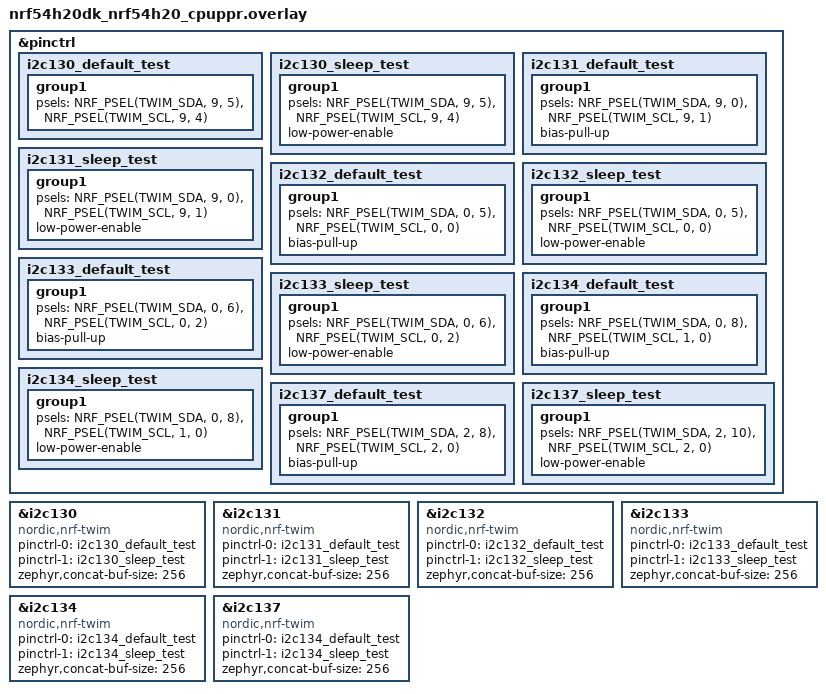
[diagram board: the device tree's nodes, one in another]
/*
 * Copyright (c) 2025 Nordic Semiconductor ASA
 *
 * SPDX-License-Identifier: LicenseRef-Nordic-5-Clause
 */

&pinctrl {
	i2c130_default_test: i2c130_default_test {
		group1 {
			psels = <NRF_PSEL(TWIM_SDA, 9, 5)>,
				<NRF_PSEL(TWIM_SCL, 9, 4)>;
		};
	};

	i2c130_sleep_test: i2c130_sleep_test {
		group1 {
			psels = <NRF_PSEL(TWIM_SDA, 9, 5)>,
				<NRF_PSEL(TWIM_SCL, 9, 4)>;
			low-power-enable;
		};
	};

	i2c131_default_test: i2c131_default_test {
		group1 {
			psels = <NRF_PSEL(TWIM_SDA, 9, 0)>,
				<NRF_PSEL(TWIM_SCL, 9, 1)>;
			bias-pull-up;
		};
	};

	i2c131_sleep_test: i2c131_sleep_test {
		group1 {
			psels = <NRF_PSEL(TWIM_SDA, 9, 0)>,
				<NRF_PSEL(TWIM_SCL, 9, 1)>;
			low-power-enable;
		};
	};

	i2c132_default_test: i2c132_default_test {
		group1 {
			psels = <NRF_PSEL(TWIM_SDA, 0, 5)>,
				<NRF_PSEL(TWIM_SCL, 0, 0)>;
			bias-pull-up;
		};
	};

	i2c132_sleep_test: i2c132_sleep_test {
		group1 {
			psels = <NRF_PSEL(TWIM_SDA, 0, 5)>,
				<NRF_PSEL(TWIM_SCL, 0, 0)>;
			low-power-enable;
		};
	};

	i2c133_default_test: i2c133_default_test {
		group1 {
			psels = <NRF_PSEL(TWIM_SDA, 0, 6)>,
				<NRF_PSEL(TWIM_SCL, 0, 2)>;
			bias-pull-up;
		};
	};

	i2c133_sleep_test: i2c133_sleep_test {
		group1 {
			psels = <NRF_PSEL(TWIM_SDA, 0, 6)>,
				<NRF_PSEL(TWIM_SCL, 0, 2)>;
			low-power-enable;
		};
	};

	i2c134_default_test: i2c134_default_test {
		group1 {
			psels = <NRF_PSEL(TWIM_SDA, 0, 8)>,
				<NRF_PSEL(TWIM_SCL, 1, 0)>;
			bias-pull-up;
		};
	};

	i2c134_sleep_test: i2c134_sleep_test {
		group1 {
			psels = <NRF_PSEL(TWIM_SDA, 0, 8)>,
				<NRF_PSEL(TWIM_SCL, 1, 0)>;
			low-power-enable;
		};
	};

	i2c137_default_test: i2c137_default_test {
		group1 {
			psels = <NRF_PSEL(TWIM_SDA, 2, 8)>,
				<NRF_PSEL(TWIM_SCL, 2, 0)>;
			bias-pull-up;
		};
	};

	i2c137_sleep_test: i2c137_sleep_test {
		group1 {
			psels = <NRF_PSEL(TWIM_SDA, 2, 10)>,
				<NRF_PSEL(TWIM_SCL, 2, 0)>;
			low-power-enable;
		};
	};
};

&i2c130 {
	compatible = "nordic,nrf-twim";
	status = "okay";
	pinctrl-0 = <&i2c130_default_test>;
	pinctrl-1 = <&i2c130_sleep_test>;
	pinctrl-names = "default", "sleep";
	zephyr,concat-buf-size = <256>;
};

&i2c131 {
	compatible = "nordic,nrf-twim";
	status = "okay";
	pinctrl-0 = <&i2c131_default_test>;
	pinctrl-1 = <&i2c131_sleep_test>;
	pinctrl-names = "default", "sleep";
	zephyr,concat-buf-size = <256>;
};

&i2c132 {
	compatible = "nordic,nrf-twim";
	status = "okay";
	pinctrl-0 = <&i2c132_default_test>;
	pinctrl-1 = <&i2c132_sleep_test>;
	pinctrl-names = "default", "sleep";
	zephyr,concat-buf-size = <256>;
};

&i2c133 {
	compatible = "nordic,nrf-twim";
	status = "okay";
	pinctrl-0 = <&i2c133_default_test>;
	pinctrl-1 = <&i2c133_sleep_test>;
	pinctrl-names = "default", "sleep";
	zephyr,concat-buf-size = <256>;
};

&i2c134 {
	compatible = "nordic,nrf-twim";
	status = "okay";
	pinctrl-0 = <&i2c134_default_test>;
	pinctrl-1 = <&i2c134_sleep_test>;
	pinctrl-names = "default", "sleep";
	zephyr,concat-buf-size = <256>;
};

/* i2c135 inaccessible due to cpuppr console on uart135 */

/* i2c136 inaccessible due to cpuapp console on uart136 */

&i2c137 {
	compatible = "nordic,nrf-twim";
	status = "okay";
	pinctrl-0 = <&i2c134_default_test>;
	pinctrl-1 = <&i2c134_sleep_test>;
	pinctrl-names = "default", "sleep";
	zephyr,concat-buf-size = <256>;
};
